# ADSP-SC83xW_HPC register map
Vendor: Analog Devices; Series: ADSP-SC83xW_HPC; File version: 3.0.3.517
CPU: 
Registers are 32-bit, read-write, reset 0x0 unless marked. A register's access mark holds for its fields unless they carry their own. Offsets are from the block's base; [hi:lo] are bit positions; {n}, {i} and the like mark numbered series.

## CANFD0 — Controller Access Network with Flexible Data Rate (CANFD)
Base 0x31046000
Same registers: CANFD1 0x31047000
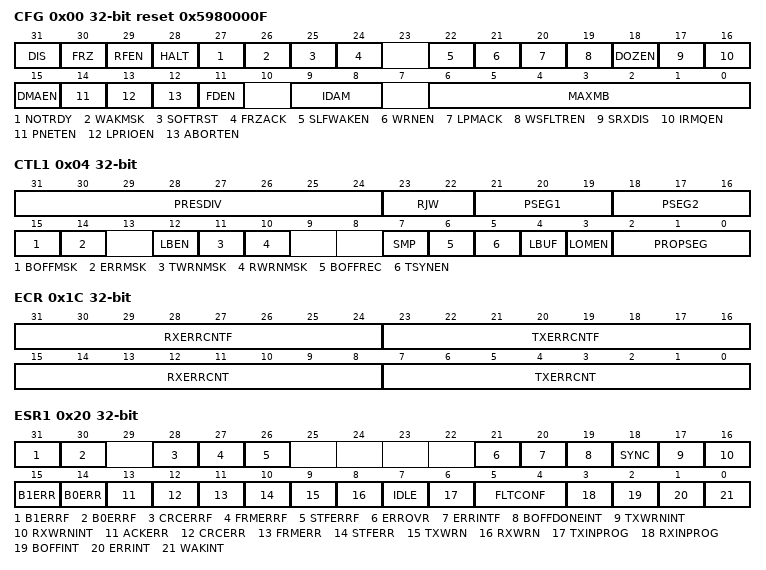
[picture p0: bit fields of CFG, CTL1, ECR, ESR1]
0x00 CFG reset 0x5980000F — Module Configuration Register
  [31] DIS — Module Disable
  [30] FRZ — Freeze Mode Enable
  [29] RFEN — Rx FIFO Enable
  [28] HALT — Freeze Mode Enable
  [27] NOTRDY ro — CANFD Not Ready
  [26] WAKMSK — Wakeup Interrupt Mask
  [25] SOFTRST range 0x00000000..0x00000001 — Soft Reset
  [24] FRZACK ro — Freeze Mode Acknowledge
  [22] SLFWAKEN — Self Wakeup Enable
  [21] WRNEN — Warning Interrupt Enable
  [20] LPMACK ro — Low Power Mode Acknowledge
  [19] WSFLTREN — Wakeup Source
  [18] DOZEN — Doze Mode Enable
  [17] SRXDIS — Self Reception Disable
  [16] IRMQEN — Rx Masking and Queue Enable
  [15] DMAEN — DMA Enable
  [14] PNETEN — Pretended Networking Enable
  [13] LPRIOEN — Local Priority Enable
  [12] ABORTEN — Abort Enable
  [11] FDEN — CANFD Enable
  [9:8] IDAM — ID Acceptance Mode
    0=FormatA; 1=FormatB; 2=FormatC; 3=FormatD
  [6:0] MAXMB range 0x00000000..0x0000007F — Number of the Last Message Buffer
0x04 CTL1 — Control 1 Register
  [31:24] PRESDIV range 0x00000000..0x000000FF — Prescaler Division Factor
  [23:22] RJW range 0x00000000..0x00000003 — Resync Jump Width
  [21:19] PSEG1 range 0x00000000..0x00000007 — Phase Segment 1
  [18:16] PSEG2 range 0x00000000..0x00000007 — Phase Segment 2
  [15] BOFFMSK — Bus-Off Interrupt Mask
  [14] ERRMSK — Error Interrupt Mask
  [12] LBEN range 0x00000000..0x00000001 — Loop-Back Mode
  [11] TWRNMSK — Tx Warning Interrupt Mask
  [10] RWRNMSK — Rx Warning Interrupt Mask
  [7] SMP — CAN Bit Sampling
  [6] BOFFREC — Bus-Off Recovery
  [5] TSYNEN — Timer Sync
  [4] LBUF — Lowest Buffer Transmitted First
  [3] LOMEN — Listen-Only Mode
  [2:0] PROPSEG range 0x00000000..0x00000007 — Propagation Segment
0x08 TMR — Free Running Timer Register
  [15:0] VALUE range 0x00000000..0x0000FFFF — Timer Value
0x10 RX_MB_GMSK — Receive Mailbox Global Mask Register
  [31:0] MBnn — Rx Mailboxes Global Mask Value
0x14 RX_14_MSK — Receive Mailbox14 Mask Register
  [31:0] MSKVAL range 0x00000000..0xFFFFFFFF — RX14 Mask Value
0x18 RX_15_MSK — Receive Mailbox15 Mask Register
  [31:0] MSKVAL range 0x00000000..0xFFFFFFFF — RX15 Mask Value
0x1C ECR — Error Counter Register
  [31:24] RXERRCNTF range 0x00000000..0x000000FF — Receive Error Counter for Fast Bits
  [23:16] TXERRCNTF range 0x00000000..0x000000FF — Transmit Error Counter for Fast Bits
  [15:8] RXERRCNT range 0x00000000..0x000000FF — Receive Error Counter
  [7:0] TXERRCNT range 0x00000000..0x000000FF — Transmit Error Counter
0x20 ESR1 — Error and Status 1 Register
  [31] B1ERRF ro — Bit 1 Error BRS
  [30] B0ERRF ro — Bit 0 Error BRS
  [28] CRCERRF ro — Cyclic Redundancy Check Error BRS
  [27] FRMERRF ro — Form Error BRS
  [26] STFERRF ro — Stuffing Error BRS
  [21] ERROVR ro — Error Overrun
  [20] ERRINTF ro — Error Interrupt BRS
  [19] BOFFDONEINT ro — Bus Off Done Interrupt
  [18] SYNC ro — CAN Synchronization Status
  [17] TXWRNINT ro — Tx Warning Interrupt Flag
  [16] RXWRNINT ro — Rx Warning Interrupt Flag
  [15] B1ERR ro — Bit 1 Error
  [14] B0ERR ro — Bit 0 Error
  [13] ACKERR ro — Acknowledge Error
  [12] CRCERR ro — Cyclic Redundancy Check Error
  [11] FRMERR ro — Form Error
  [10] STFERR ro — Stuffing Error
  [9] TXWRN ro — TX Error Warning
  [8] RXWRN ro — Rx Error Warning
  [7] IDLE ro
  [6] TXINPROG ro — CANFD in Transmission
  [5:4] FLTCONF ro — Fault Confinement State
  [3] RXINPROG ro — CANFD in Reception
  [2] BOFFINT ro — Bus Off Interrupt
  [1] ERRINT ro — Error Interrupt
  [0] WAKINT ro — Wake Up Interrupt
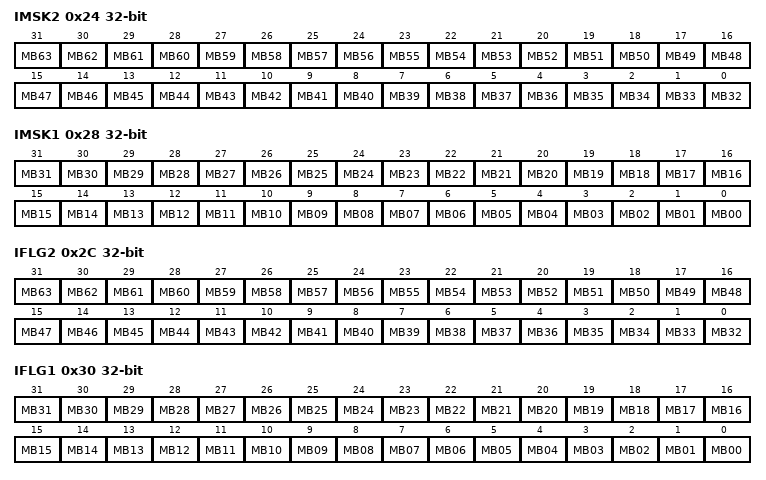
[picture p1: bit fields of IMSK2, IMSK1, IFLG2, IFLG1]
0x24 IMSK2 — Mailbox Interrupt Mask 2 Register
  [n-32] MB{n} range 0x00000000..0x00000001 (n=32..63) — Message Buffer {n} Interrupt Mask
0x28 IMSK1 — Mailbox Interrupt Mask 1 Register
  [n] MB{n:02} range 0x00000000..0x00000001 (n=0..31) — MB{n:02}[0:0] Message Buffer {n:02} Interrupt Mask
0x2C IFLG2 — Mailbox Interrupt Flag 2 Register
  [n-32] MB{n} ro (n=32..63) — MB{n}[0:0] Message Buffer {n} Interrupt Flag
0x30 IFLG1 — Mailbox Interrupt Flag 1 Register
  [n] MB{n:02} ro (n=8..31) — MB{n:02}[0:0] Message Buffer {n} Interrupt Flag
  [7] MB07 ro — Message Buffer 7 Interrupt Flag or Rx FIFO Overflow
  [6] MB06 ro — Message Buffer 6 Interrupt Flag or Rx FIFO Warning
  [5] MB05 ro — Message Buffer 5 Interrupt Flag or Frames Available in Rx FIFO
  [n] MB{n:02} ro (n=1..4) — MB{n:02}[0:0] Message Buffer {n} Interrupt Flag or Reserved
  [0] MB00 ro — Message Buffer 0 Interrupt Flag or Clear FIFO
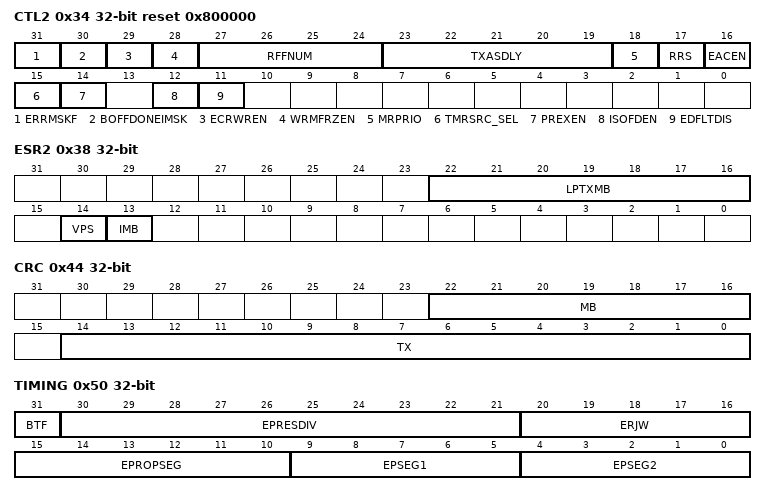
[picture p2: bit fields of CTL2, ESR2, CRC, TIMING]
0x34 CTL2 reset 0x800000 — Control 2 Register
  [31] ERRMSKF range 0x00000000..0x00000001 — Error Interrupt Mask Fast Frames
  [30] BOFFDONEIMSK range 0x00000000..0x00000001 — Bus Off Done Interrupt Mask
  [29] ECRWREN range 0x00000000..0x00000001 — Error-Correction Configuration Register Write Enable
  [28] WRMFRZEN range 0x00000000..0x00000001 — Write-Access To Memory In Freeze Mode
  [27:24] RFFNUM range 0x00000000..0x0000000F — Number Of Rx FIFO Filters
  [23:19] TXASDLY range 0x00000000..0x0000001F — Tx Arbitration Start Delay
  [18] MRPRIO range 0x00000000..0x00000001 — Mailboxes Reception Priority
  [17] RRS range 0x00000000..0x00000001 — Remote Request Storing
  [16] EACEN range 0x00000000..0x00000001 — Entire Frame Arbitration Field Comparison Enable For Rx Mailboxes
  [15] TMRSRC_SEL range 0x00000000..0x00000001 — Timer Source
  [14] PREXEN — Protocol Exception Enable
  [12] ISOFDEN range 0x00000000..0x00000001 — ISO CAN FD Enable
  [11] EDFLTDIS — Edge Filter Disable
0x38 ESR2 — Error and Status 2 Register
  [22:16] LPTXMB ro — Lowest Priority Tx Mailbox
  [14] VPS ro — Valid Priority Status
  [13] IMB ro — Inactive Mailbox
0x44 CRC
  [22:16] MB ro — CRC Mailbox
  [14:0] TX ro — Transmitted CRC Value
0x48 RX_FIFO_GMSK — Receive FIFO Global Mask Register
  [31:0] VALUE range 0x00000000..0xFFFFFFFF — Rx FIFO Global Mask Bits
0x4C RX_FIFO — Receive FIFO Information Register
  [8:0] IDHIT ro — Identifier Acceptance Filter Hit Indicator
0x50 TIMING — Can Bit Timing Register
  [31] BTF — Bit Timing Format Enable
  [30:21] EPRESDIV range 0x00000000..0x000003FF — Extended Prescaler Division Factor
  [20:16] ERJW range 0x00000000..0x0000001F — Extended Resync Jump Width
  [15:10] EPROPSEG range 0x00000000..0x0000003F — Extended Propagation Segment
  [9:5] EPSEG1 range 0x00000000..0x0000001F — Extended Phase Segment 1
  [4:0] EPSEG2 range 0x00000000..0x0000001F — Extended Phase Segment 2
{0x880+4i} RX_IMSK[{i}] (i=0..63) — Receive Individual Mask Register
  [31:0] IM range 0x00000000..0xFFFFFFFF — Individual Mask Bits
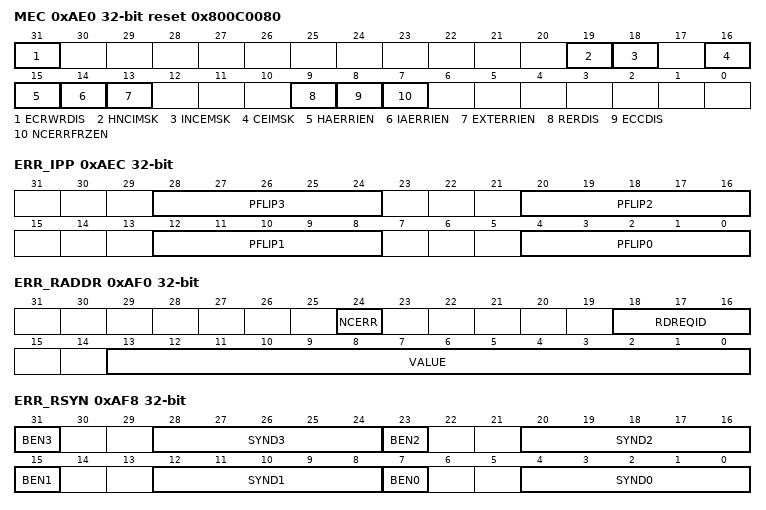
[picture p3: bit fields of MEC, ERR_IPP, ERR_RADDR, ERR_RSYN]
0xAE0 MEC reset 0x800C0080 — Memory Error Control Register
  [31] ECRWRDIS — Error Configuration Register Write Disable
  [19] HNCIMSK — Host Access With Non-Correctable Errors Interrupt Mask
  [18] INCEMSK — Internal CAN Access With Non-Correctable Errors Interrupt Mask
  [16] CEIMSK — Correctable Errors Interrupt Mask
  [15] HAERRIEN — Host Access Error Injection Enable
  [14] IAERRIEN — Internal CAN Access Error Injection Enable
  [13] EXTERRIEN — Extended Error Injection Enable
  [9] RERDIS — Error Report Disable
  [8] ECCDIS — Error Correction Disable
  [7] NCERRFRZEN — Non-Correctable Errors Freeze Mode
0xAE4 ERR_IADDR — Error Injection Address Register
  [13:0] VALUE range 0x00000000..0x00003FFF — Error Injection Address
0xAE8 ERR_IDP — Error Injection Data Pattern Register
  [31:0] DFLIP range 0x00000000..0xFFFFFFFF — Data Flip Pattern
0xAEC ERR_IPP — Error Injection Parity Pattern Register
  [8n+4:8n] PFLIP{n} range 0x00000000..0x0000001F (n=0..3) — Parity Flip Pattern Byte {n}
0xAF0 ERR_RADDR — Error Report Address Register
  [24] NCERR ro — Non-Correctable Error
  [18:16] RDREQID ro — Read Request ID
  [13:0] VALUE ro — Error Detection Address
0xAF4 ERR_RDAT — Error Report Data Register
  [31:0] VALUE ro — Raw Data Word with Error
0xAF8 ERR_RSYN — Error Report Syndrome Register
  [8n+7] BEN{n} ro (n=0..3) — Byte {n} Enabled
  [8n+4:8n] SYND{n} ro (n=0..3) — Byte {n} Error Syndrome
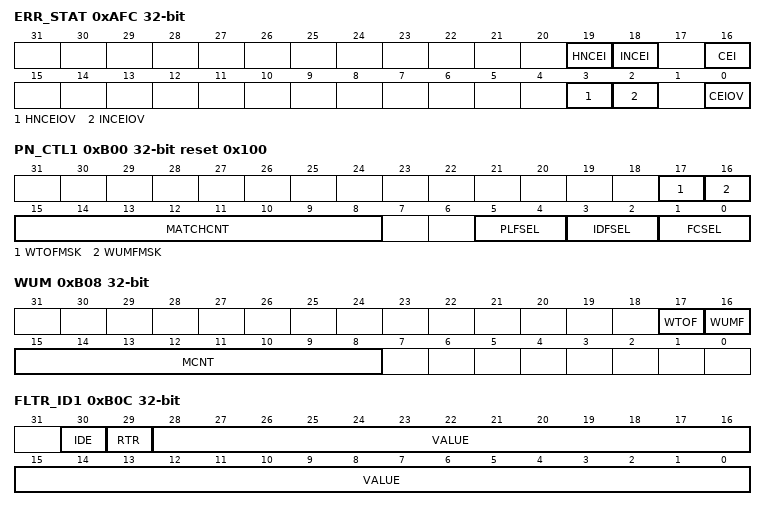
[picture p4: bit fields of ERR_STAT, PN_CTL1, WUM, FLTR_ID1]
0xAFC ERR_STAT — Error Status Register
  [19] HNCEI ro — Host Access With Non-Correctable Error Interrupt Flag
  [18] INCEI ro — Internal CAN Access With Non-Correctable Error Interrupt Flag
  [16] CEI ro — Correctable Error Interrupt Flag
  [3] HNCEIOV ro — Host Access With Non-Correctable Error Interrupt Overrun Flag
  [2] INCEIOV ro — Internal CAN Access With Non-Correctable Error Interrupt Overrun Flag
  [0] CEIOV ro — Correctable Error Interrupt Overrun Flag
0xB00 PN_CTL1 reset 0x100 — Pretended Networking Control1 Register
  [17] WTOFMSK — Wake Up by Timeout Flag Mask
  [16] WUMFMSK — Wake Up by Match Flag Mask
  [15:8] MATCHCNT range 0x00000000..0x000000FF — Number of Messages Matching Same Filtering Criteria
  [5:4] PLFSEL — Payload Filtering Selection
  [3:2] IDFSEL — ID Filtering Selection
  [1:0] FCSEL — Filtering Combination Selection
0xB04 PN_CTL2 — Pretended Networking Control2 Register
  [15:0] MATCHTO range 0x00000000..0x0000FFFF — Timeout for No Message Matching the Filtering Criteria
0xB08 WUM — Pretended Networking Wakeup Match Register
  [17] WTOF ro — Wake Up by Timeout Flag Bit
  [16] WUMF ro — Wake Up by Match Flag Bit
  [15:8] MCNT ro — Number of Matches in Pretended Networking
0xB0C FLTR_ID1 — Pretended Networking ID Filter1 Register
  [30] IDE — ID Extended Filter
  [29] RTR — Remote Transmission Request Filter
  [28:0] VALUE range 0x00000000..0x1FFFFFFF — ID Filter 1 for Pretended Networking Filtering
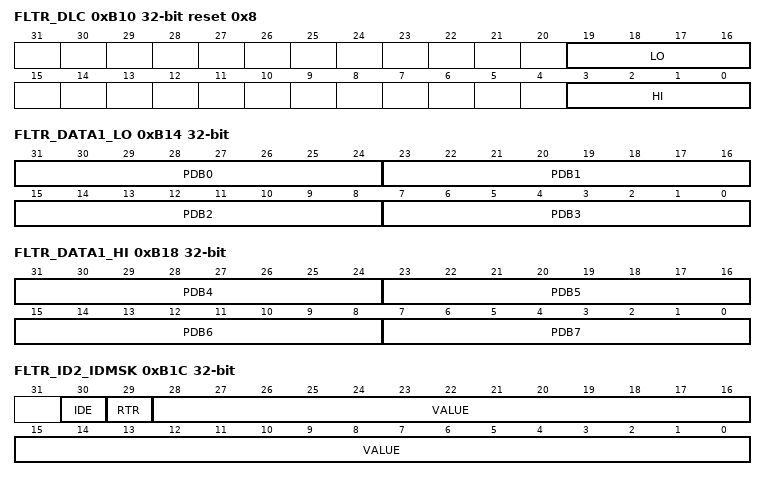
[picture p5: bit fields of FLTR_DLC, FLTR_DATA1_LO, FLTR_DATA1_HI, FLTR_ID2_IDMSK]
0xB10 FLTR_DLC reset 0x8 — Pretended Networking DLC Filter Register
  [19:16] LO range 0x00000000..0x0000000F — Lower Limit for Length of Data Bytes Filter
  [3:0] HI range 0x00000000..0x0000000F — Upper Limit for Length of Data Bytes Filter
0xB14 FLTR_DATA1_LO — Pretended Networking Payload Low Filter1 Register
  [31-8n:24-8n] PDB{n} range 0x00000000..0x000000FF (n=0..3) — Payload Filter 1 Byte {n}
0xB18 FLTR_DATA1_HI — Pretended Networking Payload Low Filter2 Register
  [63-8n:56-8n] PDB{n} range 0x00000000..0x000000FF (n=4..7) — Payload Filter 1 Byte {n}
0xB1C FLTR_ID2_IDMSK — Pretended Networking ID Filter2 / IDMask Register
  [30] IDE — ID Extended Mask Bit
  [29] RTR — Remote Transmission Request Mask Bit
  [28:0] VALUE range 0x00000000..0x1FFFFFFF — ID Filter 2 / ID Mask Bits for Pretended Networking Filtering
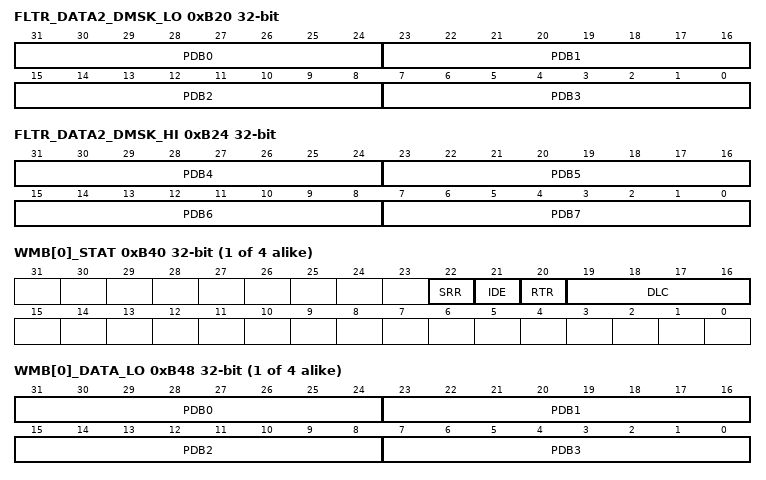
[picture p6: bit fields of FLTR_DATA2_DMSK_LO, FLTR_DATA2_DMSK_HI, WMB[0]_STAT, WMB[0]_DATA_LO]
0xB20 FLTR_DATA2_DMSK_LO — Pretended Networking Payload Low Filter2 / Payload Low Mask Register
  [31-8n:24-8n] PDB{n} range 0x00000000..0x000000FF (n=0..3) — Payload Filter 2 or Payload Mask Byte {n}
0xB24 FLTR_DATA2_DMSK_HI — Pretended Networking Payload High Filter2 High Order Bits / Payload High Mask Register
  [63-8n:56-8n] PDB{n} range 0x00000000..0x000000FF (n=4..7) — Payload Filter 2 or Payload Mask Byte {n}
{0xB40+0x10*i} WMB[{i}]_STAT (i=0..3) — Wakeup Message Buffer Control/Status Register
  [22] SRR ro — Substitute Remote Request
  [21] IDE ro — ID Extended Bit
  [20] RTR ro — Remote Transmission Request Bit
  [19:16] DLC ro — Length of Data in Bytes
{0xB44+0x10*i} WMB[{i}]_ID (i=0..3) — Wakeup Message ID Buffer Register
  [28:0] RCVID range 0x00000000..0x1FFFFFFF — Received ID Pretended Networking Mode
{0xB48+0x10*i} WMB[{i}]_DATA_LO (i=0..3) — Wakeup Message Buffer Data 0-3 Register
  [31-8n:24-8n] PDB{n} ro (n=0..3) — Payload Data Byte {n}
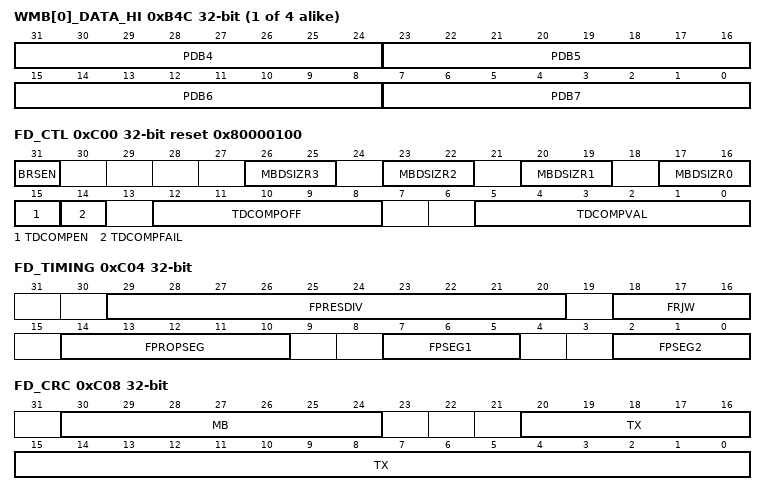
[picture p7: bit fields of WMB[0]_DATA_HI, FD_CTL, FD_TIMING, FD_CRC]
{0xB4C+0x10*i} WMB[{i}]_DATA_HI (i=0..3) — Wakeup Message Buffer Data 4-7 Register
  [63-8n:56-8n] PDB{n} ro (n=4..7) — Payload Data Byte {n}
0xC00 FD_CTL reset 0x80000100 — CANFD Control Register
  [31] BRSEN — Bit Rate Switch Enable
  [26:25] MBDSIZR3 — Message Buffer Data Size for Region 3
  [23:22] MBDSIZR2 — Message Buffer Data Size for Region 2
  [20:19] MBDSIZR1 — Message Buffer Data Size for Region 1
  [17:16] MBDSIZR0 — Message Buffer Data Size Region 0
  [15] TDCOMPEN — Transceiver Delay Compensation Enable
  [14] TDCOMPFAIL ro — Transceiver Delay Compensation Fail
  [12:8] TDCOMPOFF range 0x00000000..0x0000001F — Transceiver Delay Compensation Offset
  [5:0] TDCOMPVAL ro — Transceiver Delay Compensation Value
0xC04 FD_TIMING — CANFD Bit Timing Register
  [29:20] FPRESDIV range 0x00000000..0x000003FF — Fast Prescaler Division Factor
  [18:16] FRJW range 0x00000000..0x00000007 — Fast Resync Jump Width
  [14:10] FPROPSEG range 0x00000000..0x0000001F — Fast Propagation Segment
  [7:5] FPSEG1 range 0x00000000..0x00000007 — Fast Phase Segment 1
  [2:0] FPSEG2 range 0x00000000..0x00000007 — Fast Phase Segment 2
0xC08 FD_CRC — CANFD CRC Register
  [30:24] MB range 0x00000000..0x0000007F — CRC Mailbox Number for FD_TXCRC
  [20:0] TX range 0x00000000..0x001FFFFF — Extended Transmitted CRC value
